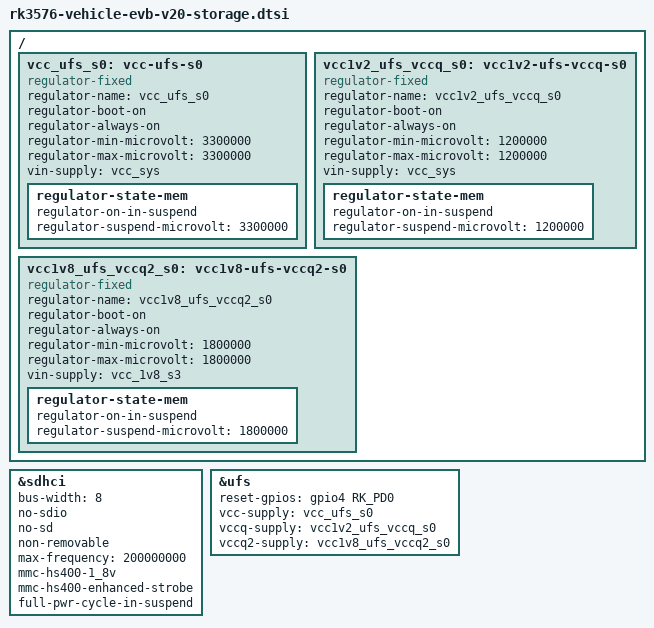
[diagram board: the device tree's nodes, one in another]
// SPDX-License-Identifier: (GPL-2.0+ OR MIT)
/*
 * Copyright (c) 2025 Rockchip Electronics Co., Ltd.
 *
 */

/ {

	vcc_ufs_s0: vcc-ufs-s0 {
		compatible = "regulator-fixed";
		regulator-name = "vcc_ufs_s0";
		regulator-boot-on;
		regulator-always-on;
		regulator-min-microvolt = <3300000>;
		regulator-max-microvolt = <3300000>;
		vin-supply = <&vcc_sys>;
		regulator-state-mem {
			regulator-on-in-suspend;
			regulator-suspend-microvolt = <3300000>;
		};
	};

	vcc1v2_ufs_vccq_s0: vcc1v2-ufs-vccq-s0 {
		compatible = "regulator-fixed";
		regulator-name = "vcc1v2_ufs_vccq_s0";
		regulator-boot-on;
		regulator-always-on;
		regulator-min-microvolt = <1200000>;
		regulator-max-microvolt = <1200000>;
		vin-supply = <&vcc_sys>;
		regulator-state-mem {
			regulator-on-in-suspend;
			regulator-suspend-microvolt = <1200000>;
		};
	};

	vcc1v8_ufs_vccq2_s0: vcc1v8-ufs-vccq2-s0 {
		compatible = "regulator-fixed";
		regulator-name = "vcc1v8_ufs_vccq2_s0";
		regulator-boot-on;
		regulator-always-on;
		regulator-min-microvolt = <1800000>;
		regulator-max-microvolt = <1800000>;
		vin-supply = <&vcc_1v8_s3>;
		regulator-state-mem {
			regulator-on-in-suspend;
			regulator-suspend-microvolt = <1800000>;
		};
	};
};

&sdhci {
	bus-width = <8>;
	no-sdio;
	no-sd;
	non-removable;
	max-frequency = <200000000>;
	mmc-hs400-1_8v;
	mmc-hs400-enhanced-strobe;
	full-pwr-cycle-in-suspend;
	status = "okay";
};

&ufs {
	/delete-property/ assigned-clocks;
	/delete-property/ assigned-clock-parents;
	reset-gpios = <&gpio4 RK_PD0 GPIO_ACTIVE_HIGH>;
	vcc-supply = <&vcc_ufs_s0>;
	vccq-supply = <&vcc1v2_ufs_vccq_s0>;
	vccq2-supply = <&vcc1v8_ufs_vccq2_s0>;
	status = "okay";
};
